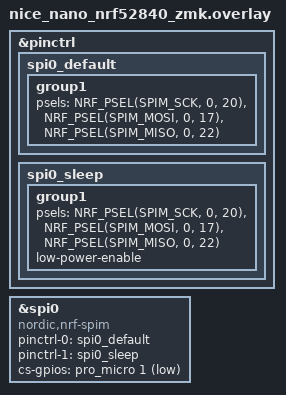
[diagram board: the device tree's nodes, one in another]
/*
 * Copyright (c) 2026 The ZMK Contributors
 * SPDX-License-Identifier: MIT
 */

&pinctrl {
    spi0_default: spi0_default {
        group1 {
            psels = <NRF_PSEL(SPIM_SCK, 0, 20)>,
                <NRF_PSEL(SPIM_MOSI, 0, 17)>,
                <NRF_PSEL(SPIM_MISO, 0, 22)>;
        };
    };
    spi0_sleep: spi0_sleep {
        group1 {
            psels = <NRF_PSEL(SPIM_SCK, 0, 20)>,
                <NRF_PSEL(SPIM_MOSI, 0, 17)>,
                <NRF_PSEL(SPIM_MISO, 0, 22)>;
            low-power-enable;
        };
    };
};

&spi0 {
    compatible = "nordic,nrf-spim";
    status = "okay";
    pinctrl-0 = <&spi0_default>;
    pinctrl-1 = <&spi0_sleep>;
    pinctrl-names = "default", "sleep";
    cs-gpios = <&pro_micro 1 GPIO_ACTIVE_LOW>;
};
